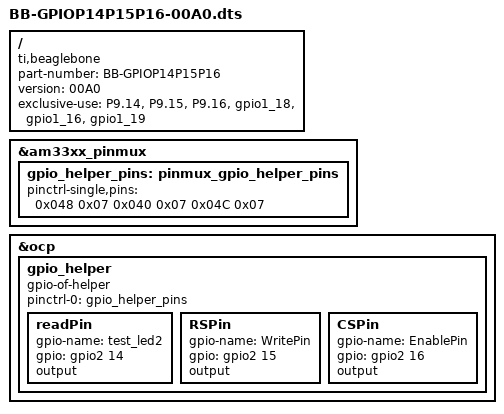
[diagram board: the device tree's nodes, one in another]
/* Copyright (C) 2013 Pantelis Antoniou <pa...@antoniou-consulting.com>
*
* This program is free software; you can redistribute it and/or modify
* it under the terms of the GNU General Public License version 2 as
* published by the Free Software Foundation.
*/
/dts-v1/;
/plugin/;

/ {
	compatible = "ti,beaglebone", "ti,beaglebone-black";

	/* identification */
	part-number = "BB-GPIOP14P15P16";
	version = "00A0";

	/* state the resources this cape uses */
	exclusive-use =
		/* the pin header uses */
		"P9.14",    /* gpio */
		"P9.15",  	/* gpio */
		"P9.16",  	/* gpio */
		/* the hardware IP uses */
		"gpio1_18",
		"gpio1_16",
		"gpio1_19";

	fragment@0 {
		target = <&am33xx_pinmux>;
		__overlay__ {
			gpio_helper_pins: pinmux_gpio_helper_pins {
				pinctrl-single,pins = <
					0x048 0x07 	/* P9.14 GPIO1_18:  MODE7 | OUTPUT */
					0x040 0x07 	/* P9.15 GPIO1_16:  MODE7 | OUTPUT */
					0x04C 0x07 	/* P9.16 GPIO1_29:  MODE7 | OUTPUT */
				>;
			};
		};	
	};

	fragment@2 {
		target = <&ocp>;
		__overlay__ {

			gpio_helper {
				compatible = "gpio-of-helper";
				status = "okay";
				pinctrl-names = "default";
				pinctrl-0 = <&gpio_helper_pins>;

				/* declare your gpios */
				readPin {
					gpio-name = "test_led2";
					gpio = <&gpio2 14 0x00>;	/* gpio2 is gpio1 */
                    output; 
                };
                RSPin { 
					gpio-name = "WritePin";
					gpio = <&gpio2 15 0x00>;	/* gpio2 is gpio1 */
                    output;
                 };
                 CSPin {
					gpio-name = "EnablePin";
					gpio = <&gpio2 16 0x00>;	/* gpio2 is gpio1 */
					output;
				};

			};
		};
	};
};
